# STM32U031xx register map
File version: 1.0
Registers are 32-bit, read-write, reset 0x0 unless marked. A register's access mark holds for its fields unless they carry their own. Offsets are from the block's base; [hi:lo] are bit positions; {n}, {i} and the like mark numbered series.

## TAMP — Tamper and backup registers
Base 0x4000B000
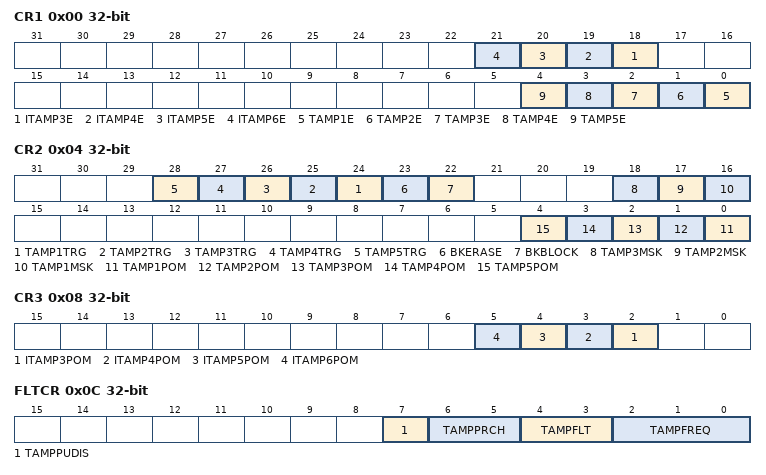
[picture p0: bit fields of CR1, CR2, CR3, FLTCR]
0x00 CR1 — TAMP configuration register 1
  [n+15] ITAMP{n}E (n=3..6), [n-1] TAMP{n}E (n=1..5)
0x04 CR2 — TAMP configuration register 2
  [n+23] TAMP{n}TRG (n=1..5), [23] BKERASE, [22] BKBLOCK, [18] TAMP3MSK, [17] TAMP2MSK, [16] TAMP1MSK, [n-1] TAMP{n}POM (n=1..5)
0x08 CR3 — TAMP configuration register 3
  [n-1] ITAMP{n}POM (n=3..6)
0x0C FLTCR — TAMP filter control register
  [7] TAMPPUDIS
  [6:5] TAMPPRCH
    0=DURATION_1RTCCLK (Tamper pins are pre-charged before sampling during 1 RTCCLK cycle); 1=DURATION_2RTCCLK (Tamper pins are pre-charged before sampling during 2 RTCCLK cycles); 2=DURATION_4RTCCLK (Tamper pins are pre-charged before sampling during 4 RTCCLK cycles); 3=DURATION_8RTCCLK (Tamper pins are pre-charged before sampling during 8 RTCCLK cycles)
  [4:3] TAMPFLT
    0=DISABLE (Tamper filter is disabled); 1=FILTER_2SAMPLE (Tamper is activated after 2 consecutive samples at the active level); 2=FILTER_4SAMPLE (Tamper is activated after 4 consecutive samples at the active level); 3=FILTER_8SAMPLE (Tamper is activated after 8 consecutive samples at the active level.)
  [2:0] TAMPFREQ
    0=SAMPLFREQDIV_32768 (Each of the tamper inputs are sampled with a frequency = RTCCLK / 32768); 1=SAMPLFREQDIV_16384 (Each of the tamper inputs are sampled with a frequency = RTCCLK / 16384); 2=SAMPLFREQDIV_8192 (Each of the tamper inputs are sampled with a frequency = RTCCLK / 8192); 3=SAMPLFREQDIV_4096 (Each of the tamper inputs are sampled with a frequency = RTCCLK / 4096); 4=SAMPLFREQDIV_2048 (Each of the tamper inputs are sampled with a frequency = RTCCLK / 2048); 5=SAMPLFREQDIV_1024 (Each of the tamper inputs are sampled with a frequency = RTCCLK / 1024); 6=SAMPLFREQDIV_512 (Each of the tamper inputs are sampled with a frequency = RTCCLK / 512); 7=SAMPLFREQDIV_256 (Each of the tamper inputs are sampled with a frequency = RTCCLK / 256)
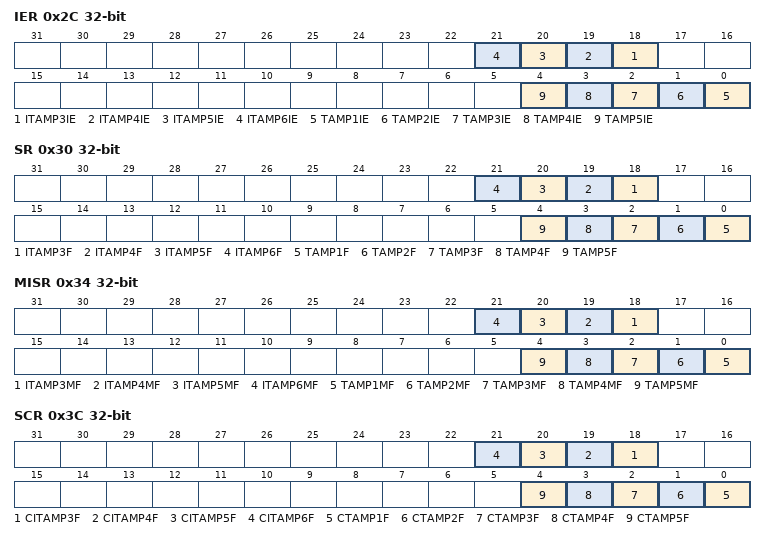
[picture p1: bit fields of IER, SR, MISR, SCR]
0x2C IER — TAMP interrupt enable register
  [n+15] ITAMP{n}IE (n=3..6), [n-1] TAMP{n}IE (n=1..5)
0x30 SR — TAMP status register
  [n+15] ITAMP{n}F (n=3..6), [n-1] TAMP{n}F (n=1..5)
0x34 MISR — TAMP masked interrupt status register
  [n+15] ITAMP{n}MF (n=3..6), [n-1] TAMP{n}MF (n=1..5)
0x3C SCR — TAMP status clear register
  [n+15] CITAMP{n}F (n=3..6), [n-1] CTAMP{n}F (n=1..5)
{0x100+4i} BKP{i}R (i=0..8) — TAMP backup register {i}

## COMP1 — Comparator
Base 0x40010200
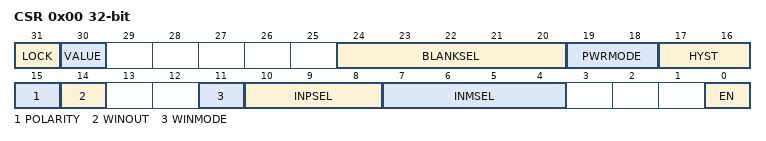
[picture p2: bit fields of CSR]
0x00 CSR — COMP control and status register
  [31] LOCK — COMPx Lock Bit
  [30] VALUE — Comparator output level
  [24:20] BLANKSEL — COMPx blanking source selection bits
    0=NONE (Comparator output without blanking); 1=TIM1_OC4 (Comparator output blanking source TIM1 OC4 (common to all COMP instances: COMP1, COMP2)); 2=TIM1_OC5 (Comparator output blanking source TIM1 OC5 (common to all COMP instances: COMP1, COMP2)); 4=TIM2_OC3 (Comparator output blanking source TIM2 OC3 (common to all COMP instances: COMP1, COMP2)); 8=TIM3_OC3 (Comparator output blanking source TIM3 OC3 (common to all COMP instances: COMP1, COMP2)); 16=TIM15_OC2 (Comparator output blanking source TIM15 OC2 (common to all COMP instances: COMP1, COMP2))
  [19:18] PWRMODE — COMPx Power Mode of the comparator
    0=HIGHSPEED (COMP power mode to high speed); 1=MEDIUMSPEED (COMP power mode to medium speed); 3=ULTRALOWPOWER (COMP power mode to ultra-low power)
  [17:16] HYST — COMPx hysteresis selection bits
    0=NONE (No hysteresis); 1=LOW (Hysteresis level low); 2=MEDIUM (Hysteresis level medium); 3=HIGH (Hysteresis level high)
  [15] POLARITY — COMPx polarity selection bit
    0=NONINVERTED (COMP output polarity is not inverted: comparator output is high when the plus (non-inverting) input is at a higher voltage than the minus (inverting) input); 1=INVERTED (COMP output polarity is inverted: comparator output is low when the plus (non-inverting) input is at a lower voltage than the minus (inverting) input)
  [14] WINOUT — COMPx polarity selection bit
  [11] WINMODE — COMPx Windows mode selection bit
  [10:8] INPSEL — COMPx input plus selection bit
    0=IO1 (Comparator input plus connected to IO1 (pin PC5 for COMP1, pin PB4 for COMP2)); 1=IO2 (Comparator input plus connected to IO2 (pin PB2 for COMP1, pin PB6 for COMP2)); 2=IO3 (Comparator input plus connected to IO3 (pin PA1 for COMP1, pin PA3 for COMP2)); 3=IO4 (Comparator input plus connected to IO4 (pin PA9 for COMP1, pin PD10 for COMP2)); 4=IO5 (Comparator input plus connected to IO5 (pin PC6 for COMP1))
  [7:4] INMSEL — COMPx input minus selection bit
    0=MINUS_1_4VREFINT (Comparator input minus connected to 1/4 VrefInt); 1=MINUS_1_2VREFINT (Comparator input minus connected to 1/2 VrefInt); 2=MINUS_3_4VREFINT (Comparator input minus connected to 3/4 VrefInt); 3=VREFINT (Comparator input minus connected to VrefInt); 4=DAC1_CH1 (Comparator input minus connected to DAC1 channel 1 (DAC_OUT1)); 5=IO1 (Comparator input minus connected to IO1 (pin PC4 for COMP1, pin PB7 for COMP2)); 6=IO2 (Comparator input minus connected to IO2 (pin PB1 for COMP1, pin PB3 for COMP2)); 7=IO3 (Comparator input minus connected to IO3 (pin PA0 for COMP1, pin PA2 for COMP2)); 8=IO4 (Comparator input minus connected to IO4 (pin PA4 for COMP1, pin PA4 for COMP2)); 9=IO5 (Comparator input minus connected to IO5 (pin PA5 for COMP1, pin PA5 for COMP2))
  [0] EN — COMPx enable bit
